# TC37XPD register map
Vendor: Infineon; Series: ATVMC; File version: 100
CPU: other r0p0, little endian, MPU, FPU, vendor SysTick, 4 interrupt priority bits
Registers are 32-bit, read-write, reset 0x0 unless marked. A register's access mark holds for its fields unless they carry their own. Offsets are from the block's base; [hi:lo] are bit positions; {n}, {i} and the like mark numbered series.

## MSC0 — MSC
Base 0xF0002600
Same registers: MSC1 0xF0002700
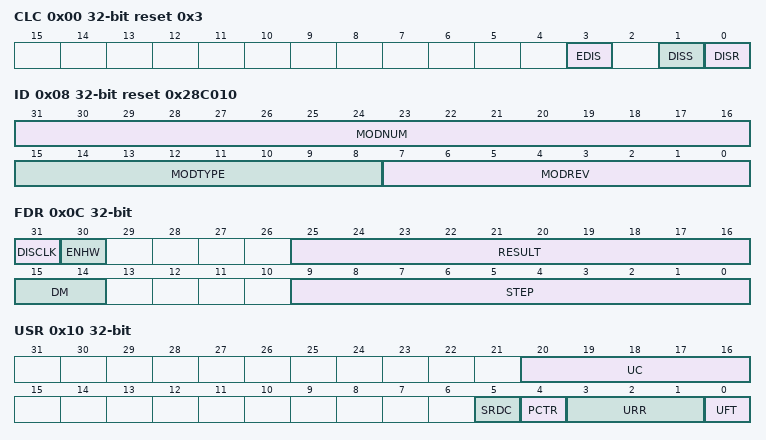
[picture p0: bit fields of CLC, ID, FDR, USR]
0x00 CLC access per field reset 0x3 — Clock Control Register resetvalue={Application Reset:0x3}
  [3] EDIS rw — Sleep Mode Enable Control EDIS. Used to control module 8217 s sleep mode.
  [1] DISS ro — Module Disable Status Bit DISS. Bit indicates the current status of the module.
  [0] DISR rw — Module Disable Request Bit DISR. Used for enable disable control of the module.
0x08 ID ro reset 0x28C010 (reset mask 0xFFFFFFF0) — Module Identification Register resetvalue={Application Reset:0x28C010}
  [31:16] MODNUM — Module Number Value MODNUM. This bit field defines the module identification number for the MSC 0028 H
  [15:8] MODTYPE — Module Type MODTYPE. This bit field defines the module as a 32 bit module C0 H
  [7:0] MODREV — Module Revision Number MODREV. This bit field defines the module revision number. The value of a module revision starts with 01 H first revision .
0x0C FDR access per field — Fractional Divider Register resetvalue={Application Reset:0x0}
  [31] DISCLK rw — Disable Clock DISCLK. Hardware controlled disable for f MSC signal.
  [30] ENHW rw — Enable Hardware Clock Control ENHW. Controls operation of ECEN input and DISCLK bit.
  [25:16] RESULT ro — Result Value RESULT. Bit field for the addition result.
  [15:14] DM rw — Divider Mode DM. DM selects normal or fractional divider mode.
  [9:0] STEP rw — Step Value STEP. Reload or addition value for RESULT.
0x10 USR access per field — Upstream Status Register resetvalue={Application Reset:0x0}
  [20:16] UC ro — Upstream Counter UC. This bit field indicates the content of the upstream counter that counts the bits during upstream channel reception.
  [5] SRDC rw — Service Request Delay Control SRDC. This bit determines the additional delay inserted by the upstream channel when triggering the receive interrupt. Only the hardware generated interrupt can be delayed. The software generated interrupt by writing the ISC.SURDI bit is never delayed.
  [4] PCTR rw — Parity Control PCTR. This bit determines the parity mode used by the upstream channel for data reception.
  [3:1] URR rw — Upstream Channel Receiving Rate URR. This bit field determines the baud rate for the upstream channel.
  [0] UFT rw — Upstream Channel Frame Type UFT. This bit determines the frame type used by the upstream channel for data reception.
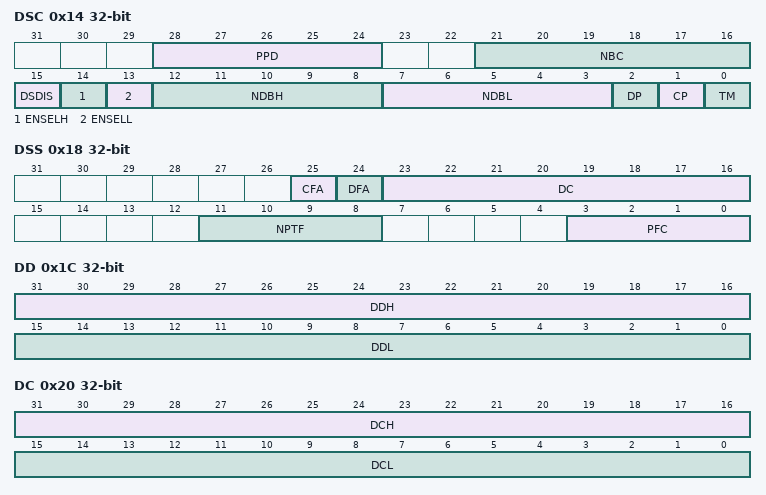
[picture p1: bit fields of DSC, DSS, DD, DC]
0x14 DSC access per field — Downstream Control Register resetvalue={Application Reset:0x0}
  [28:24] PPD rw — Passive Phase Length at Data Frames PPD. This bit field determines the length of the passive phase of a data frame.
  [21:16] NBC rw — Number of Bits Shifted at Command Frames NBC. This bit field determines how many bits of the SRL SRH shift registers are shifted out during transmission of a command frame.
  [15] DSDIS ro — Downstream Disable DSDIS. This bit indicates the state of the downstream channel operation.
  [14] ENSELH rw — Enable SRH Active Phase Selection Bit ENSELH. This bit determines whether a low level selection bit is inserted at the beginning of a data frame 8217 s SRH active phase.
  [13] ENSELL rw — Enable SRL Active Phase Selection Bit ENSELL. This bit determines whether a low level selection bit is inserted at the beginning of a data frame 8217 s SRL active phase.
  [12:8] NDBH rw — Number of SRH Bits Shifted at Data Frames NDBH. NDBH determines the number of shift register high part SRH bits that are shifted out on SO during a data frame. Other bit combinations are reserved do not use these bit combinations.
  [7:3] NDBL rw — Number of SRL Bits Shifted at Data Frames NDBL. NDBL determines the number of shift register low part SRL bits that are shifted out on SO during a data frame. Other bit combinations are reserved do not use these bit combinations.
  [2] DP ro — Data Pending DP. In Triggered Mode this bit is set when the set data pending bit ISC.SDP is set by software. In Data Repetition Mode this bit is set by hardware at the last passive time frame. At the start of the data frame DP is cleared by hardware.
  [1] CP ro — Command Pending CP. This bit is set when the downstream command register DC is written. CP is cleared when the first bit of the related command frame is sent out.
  [0] TM rw — Transmission Mode TM. This bit selects the transmission mode of the downstream channel.
0x18 DSS access per field — Downstream Status Register resetvalue={Application Reset:0x0}
  [25] CFA ro — Command Frame Active CFA. This bit indicates if a command frame is currently sent out active phase only.
  [24] DFA ro — Data Frame Active DFA. This bit indicates if a data frame is currently sent out active phase only.
  [23:16] DC ro — Downstream Counter DC. This bit field indicates the number of downstream shift clock periods that have been elapsed since the start of the current frame. DC is reset at the end of a downstream frame.
  [11:8] NPTF rw — Number Of Passive Time Frames NPTF. This bit field indicates the number of passive time frames that are inserted in Data Repetition Mode between two data frames.
  [3:0] PFC ro — Passive Time Frame Counter PFC. In Data Repetition Mode this bit field indicates the count of passive time frames that are currently transmitted. In Triggered Mode PFC remains at 0000 B .
0x1C DD — Downstream Data Register resetvalue={Application Reset:0x0}
  [31:16] DDH — Downstream Data for SRH Shift Register DDH. Contains the data bits to be transmitted during the SRH active phase of a data frame.
  [15:0] DDL — Downstream Data for SRL Shift Register DDL. Contains the data bits to be transmitted during the SRL active phase of a data frame.
0x20 DC — Downstream Command Register resetvalue={Application Reset:0x0}
  [31:16] DCH — Downstream Command for SRH Shift Register DCH. Contains the data bits to be transmitted during the SRH active phase of a command frame.
  [15:0] DCL — Downstream Command for SRL Shift Register DCL. Contains the data bits to be transmitted during the SRL active phase of a command frame.
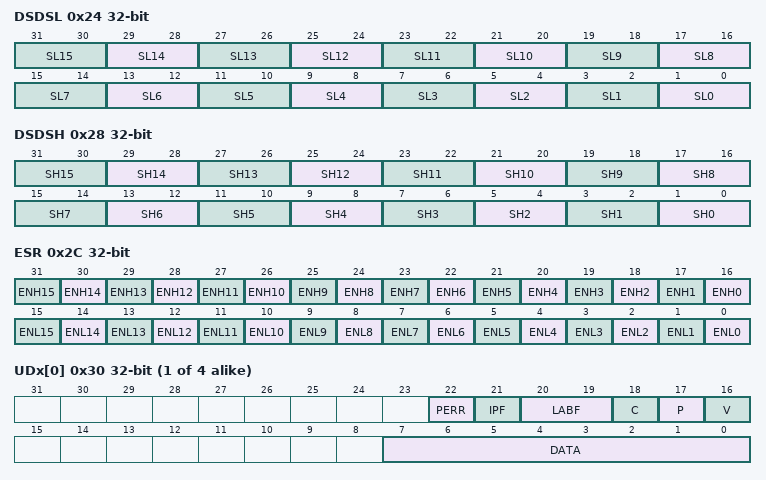
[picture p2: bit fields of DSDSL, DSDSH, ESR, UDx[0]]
0x24 DSDSL — Downstream Select Data Source Low Register resetvalue={Application Reset:0x0}
  [2n+1:2n] SL{n} (n=0..15) — Select Source for SRL SL15. SLx determines which data source is used for the shift register bit SRL x for data frame transmission.
0x28 DSDSH — Downstream Select Data Source High Register resetvalue={Application Reset:0x0}
  [2n+1:2n] SH{n} (n=0..15) — Select Source for SRH SH15. SHx determines which data source is used for the shift register bit SRH x during data frame transmission.
0x2C ESR — Emergency Stop Register resetvalue={Application Reset:0x0}
  [n+16] ENH{n} (n=0..15) — Emergency Stop Enable for Bit 15 in SRH ENH15. This bit enables the emergency stop feature selectively for each SRH bit. If the emergency stop condition is met and enabled ENHx 1 the SRH x bit of the data register DD.DDH x is used for the shift register load operation.
  [n] ENL{n} (n=0..15) — Emergency Stop Enable for Bit 15 in SRL ENL15. This bit enables the emergency stop feature selectively for each SRL bit. If the emergency stop condition is met and enabled ENLx 1 the SRL x bit of the data register DD.DDL x is used for the shift register load operation.
{0x30+4i} UDx[{i}] (i=0..3) access per field — Upstream Data Register 0 resetvalue={Application Reset:0x0}
  [22] PERR ro — Parity Error PERR. This bit indicates if a start bit error parity error or stop bit error occurred during frame reception.
  [21] IPF ro — Internal Parity Flag IPF. This bit contains the parity bit that has been calculated in the MSC during data frame reception.
  [20:19] LABF ro — Lower Address Bit Field LABF. This bit field contains the two address bits A 1 0 of the 4 bit address field 16 bit data frame . If 12 bit data frame is selected LABF is always set to 00 B .
  [18] C wo — Clear Bit C. C is always read as 0.
  [17] P ro — Parity Bit P. This flag contains the parity bit that has been received with the data frame.
  [16] V ro — Valid Bit V. This bit is set by hardware when the received data is written to UDx. Writing bit C 1 clears V. If hardware setting and software clearing of the valid bit occur simultaneously bit V will be cleared.
  [7:0] DATA ro — Received Data DATA. This bit field contains the 8 bit receive data.
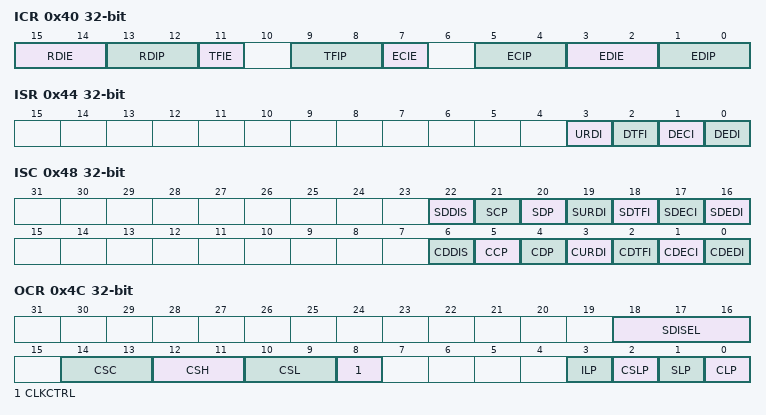
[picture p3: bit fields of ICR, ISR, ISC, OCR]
0x40 ICR — Interrupt Control Register resetvalue={Application Reset:0x0}
  [15:14] RDIE — Receive Data Interrupt Enable RDIE. This bit field determines the enable conditions for the receive data interrupt.
  [13:12] RDIP — Receive Data Interrupt Pointer RDIP. RDIP selects the service request output line SRn n 0 3 for the receive data interrupt.
  [11] TFIE — Time Frame Interrupt Enable TFIE. This bit enables the time frame interrupt.
  [9:8] TFIP — Time Frame Interrupt Pointer TFIP. TFIP selects the service request output line SRn n 0 3 for the time frame interrupt.
  [7] ECIE — Command Frame Interrupt Enable ECIE. This bit enables the command frame interrupt.
  [5:4] ECIP — Command Frame Interrupt Node Pointer ECIP. ECIP selects the service request output line SRn n 0 3 for the command frame interrupt.
  [3:2] EDIE — Data Frame Interrupt Enable EDIE. This bit field determines the enable conditions for the data frame interrupt.
  [1:0] EDIP — Data Frame Interrupt Node Pointer EDIP. EDIP selects the service request output line SRn n 0 3 for the data frame interrupt.
0x44 ISR ro — Interrupt Status Register resetvalue={Application Reset:0x0}
  [3] URDI — Receive Data Interrupt Flag URDI. This flag is always set by hardware when an upstream channel receive data interrupt is generated whether or not it is enabled. URDI can be set or cleared by software when writing to register ISC with the appropriate bits SURDI or CURDI set.
  [2] DTFI — Time Frame Interrupt Flag DTFI. This flag is always set by hardware when a downstream channel time frame interrupt is generated whether or not it is enabled. DTFI can be set or cleared by software when writing to register ISC with the appropriate bits SDTFI or CDTFI set.
  [1] DECI — Command Frame Interrupt Flag DECI. This flag is always set by hardware when a downstream channel command frame interrupt is generated whether or not it is enabled. DECI can be set or cleared by software when writing to register ISC with the appropriate bits SDECI or CDECI set.
  [0] DEDI — Data Frame Interrupt Flag DEDI. This flag is always set by hardware when a downstream channel data frame interrupt is generated. DEDI can be set or cleared by software when writing to register ISC with the appropriate bits ISC.SDEDI or ISC.CDEDI set.
0x48 ISC wo — Interrupt Set Clear Register resetvalue={Application Reset:0x0}
  [22] SDDIS — Set DSDIS Flag SDDIS
  [21] SCP — Set CP Flag SCP
  [20] SDP — Set DP Bit SDP
  [19] SURDI — Set URDI Flag SURDI
  [18] SDTFI — Set DTFI Flag SDTFI
  [17] SDECI — Set DECI Flag SDECI
  [16] SDEDI — Set DEDI Flag SDEDI
  [6] CDDIS — Clear DSDIS Flag CDDIS
  [5] CCP — Clear CP Flag CCP
  [4] CDP — Clear DP Flag CDP
  [3] CURDI — Clear URDI Flag CURDI
  [2] CDTFI — Clear DTFI Flag CDTFI
  [1] CDECI — Clear DECI Flag CDECI
  [0] CDEDI — Clear DEDI Flag CDEDI
0x4C OCR — Output Control Register resetvalue={Application Reset:0x0}
  [18:16] SDISEL — Serial Data Input Selection SDISEL. This bit field selects the source for the serial data input SDI of the upstream channel.
  [14:13] CSC — Chip Enable Selection for ENC CSC. This bit field selects the chip enable output ENx that becomes active during the active phase ENC 160 160 1 of a command frame. The active level of ENx is defined by bit CSLP.
  [12:11] CSH — Chip Enable Selection for ENH CSH. This bit field selects the chip enable output ENx that becomes active during the SRH active phase ENH 160 160 1 of a data frame. The active level of ENx is defined by bit CSLP.
  [10:9] CSL — Chip Enable Selection for ENL CSL. This bit field selects the chip enable output ENx that becomes active during the SRL active phase ENL 160 160 1 of a data frame. The active level of ENx is defined by bit CSLP.
  [8] CLKCTRL — Clock Control CLKCTRL. This bit determines the activation of clock output FCL.
  [3] ILP — SDI Line Polarity ILP
  [2] CSLP — Chip Selection Lines Polarity CSLP. Bit CSLP is buffered during a frame transmission. This means that any change of CSLP becomes valid first with the start of the next frame transmission.
  [1] SLP — SOP Line Polarity SLP
  [0] CLP — FCLP Line Polarity CLP
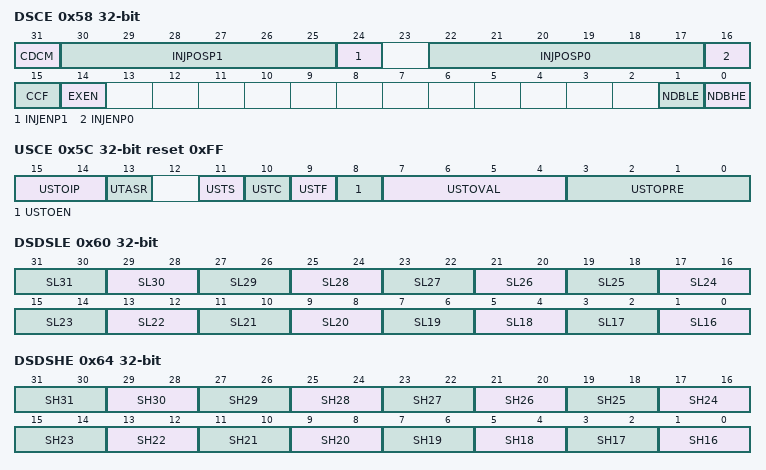
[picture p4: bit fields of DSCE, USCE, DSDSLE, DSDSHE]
0x58 DSCE access per field — Downstream Control Enhanced Register 1 resetvalue={Application Reset:0x0}
  [31] CDCM rw — Command Data Command in Data Repetition Mode CDCM. This bit selects if a data frame is automatically inserted between two consecutive command frame requests.
  [30:25] INJPOSP1 rw — Injection Position of the Pin 1 Signal INJPOSP1. This bit selects the position of the injected external one bit signal at the bit position in range of 0 to 63 in the data frame.
  [24] INJENP1 rw — Injection Enable of the Pin 1 Signal INJENP1. This bit selects if an external signal is injected in a data frame.
  [22:17] INJPOSP0 rw — Injection Position of the Pin 0 Signal INJPOSP0. This bit selects the position of the injected external one bit signal at the bit position in range of 0 to 63 in the data frame. If both PIN0POS and PIN1POS point to a same bit PIN0POS has the higher priority that is PIN0 level will be visible in the data frame.
  [16] INJENP0 rw — Injection Enable of the Pin 0 Signal INJENP0. This bit selects if an external signal is injected in a data frame.
  [15] CCF ro — Command Command Flag CCF. This bit flags that a second command frame has been written without data frame to be sent in between. It is active only if CDCM 1. Otherwise it is always low.
  [14] EXEN rw — Extension Enable EXEN. Enables the extension bit fields.
  [1] NDBLE rw — Number of SRL Bits Shifted at Data Frames Extension NDBLE. Additional MSB bit extension of the NDBL bit field. Adds 16 to the resulting NDBL value if set.
  [0] NDBHE rw — Number of SRH Bits Shifted at Data Frames Extension NDBHE. Additional MSB bit extension of the NDBH bit field. Adds 16 to the resulting NDBH value if set.
0x5C USCE access per field reset 0xFF — Upstream Control Enhanced Register 1 resetvalue={Application Reset:0x0FF}
  [15:14] USTOIP rw — Upstream Time out Interrupt Node Pointer USTOIP. USTOIP selects the service request output line SRn n 0 3 for the time out interrupt.
  [13] UTASR rw — Upstream Time out Alternate Service Request UTASR. Selects if the interrupt signal is routed to the alternate service request node. See CROSSREFERENCE .
  [11] USTS wo — Upstream Time out Set USTS. Sets the USTF flag. Write only bit reads as 0.
  [10] USTC wo — Upstream Time out Clear USTC. Clears the USTF flag. Write only bit reads as 0.
  [9] USTF ro — Upstream Time out Flag USTF. Signals an upstream timer event. If set by software the interrupt is also triggered if enabled. The watchdog timer runs continuously and sets the USTF flag at overflow independently from the enable bit. Therefore this bit must be cleared with the same write access which enables the interrupt.
  [8] USTOEN rw — Upstream Time out Interrupt Enable USTOEN. Enable bit for the upstream time out interrupt. The Time out counter runs continuously independently of the USTOEN bit. The USTOEN enables only the interrupt generation.
  [7:4] USTOVAL rw — Upstream Time out Value USTOVAL. Upstream time out value for the N divider in the range of 1 to 16 expressed in number of upstream bit time lengths the upstream bit time is the reciprocal value of the upstream baud rate . Time out BitTime 2 USTOPRE 1 USTOVAL 1 . Write to this bit field triggers new start of the watchdog timer.
  [3:0] USTOPRE rw — Upstream Time out Prescaler USTOPRE. Prescaler for the upstream time out limit. Expressed in upstream bit times. 2 n divider in the range of 1 to 16384. Write to this bit field triggers new start of the watchdog timer.
0x60 DSDSLE — Downstream Select Data Source Low Extension Register resetvalue={Application Reset:0x0}
  [2n-31:2n-32] SL{n} (n=16..31) — Select Source for SRL SL31. SLx determines which data source is used for the shift register bit SRL x during data frame transmission.
0x64 DSDSHE — Downstream Select Data Source High Extension Register resetvalue={Application Reset:0x0}
  [2n-31:2n-32] SH{n} (n=16..31) — Select Source for SRH SH31. SHx determines which data source is used for the shift register bit SRH x during data frame transmission.
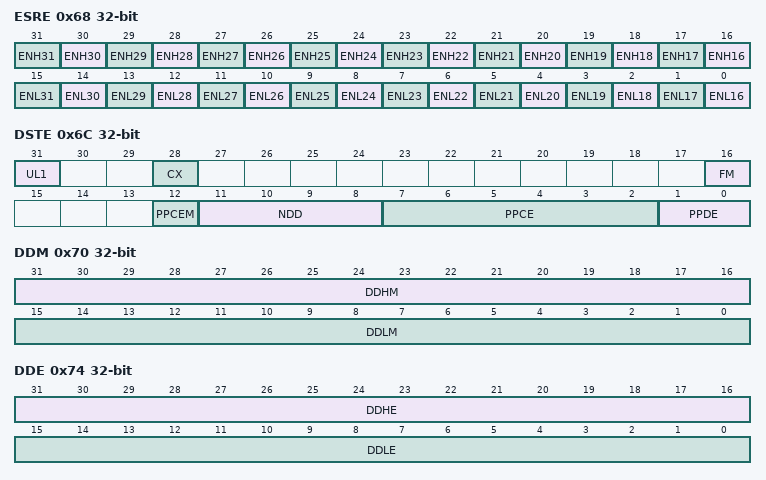
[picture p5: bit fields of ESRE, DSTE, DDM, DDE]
0x68 ESRE — Emergency Stop Extension Register resetvalue={Application Reset:0x0}
  [n] ENH{n} (n=16..31) — Emergency Stop Enable for Bit 31 in SRH ENH31. This bit enables the emergency stop feature selectively for each SRH bit. If the emergency stop condition is met and enabled ENHx 1 the SRH x bit of the data register DD.DDH x is used for the shift register load operation.
  [n-16] ENL{n} (n=16..31) — Emergency Stop Enable for Bit 31 in SRL ENL31. This bit enables the emergency stop feature selectively for each SRL bit. If the emergency stop condition is met and enabled ENLx 1 the SRL x bit is of the data register DD.DDL x is used for the shift register load operation.
0x6C DSTE access per field — Downstream Timing Extension Register resetvalue={Application Reset:0x0}
  [31] UL1 wo — Unlock CX and FM for one write access UL1. Write access with UL1 160 160 1 unlocks the CX and FM bit fields for the current write access. Write accesses to these bit fields with UL1 160 160 0 do not have any effect. Returns zero on read.
  [28] CX rw — Command Extension Mode CX. Activates 64 bit command frame feature.
  [16] FM rw — Fast Mode FM. Activates the fast mode and writing to the ABRA FIFO with 100 160 MBaud input baud rate in order to provide 80MBaud output baud rate. It is also recommended for baud rate of 26 67 160 MBaud as defined in the CROSSREFERENCE . FM 0 is the compatibility setting with the previous generations of the MSC.
  [12] PPCEM rw — PPCE Extension Bit on the MSB Side PPCEM. This bit is the MSB extension bit for the PPCE bit field extending command frame passive phase to the value of 127. The values of 128 and 129 are not allowed.
  [11:8] NDD rw — N Divider Downstream NDD. Defines the division ratio in the range of 1 to 16.
  [7:2] PPCE rw — Passive Phase Length at Control Frames Extension PPCE. Additional MSB bits extension of the fixed length of 2 of the command frames passive phase. The final length is 2 160 160 PPCE resulting in a range of 2 to 65.
  [1:0] PPDE rw — Passive Phase Length at Data Frames Extension PPDE. Additional MSB bits extension of the PPD bit field.
0x70 DDM wo — Downstream Data Mirror Register resetvalue={Application Reset:0x0}
  [31:16] DDHM — Downstream Data Mirror for SRH Shift Register DDHM. Contains the data bits to be transmitted during the SRH active phase of a data frame.
  [15:0] DDLM — Downstream Data Mirror for SRL Shift Register DDLM. Contains the data bits to be transmitted during the SRL active phase of a data frame.
0x74 DDE — Downstream Data Extension Register resetvalue={Application Reset:0x0}
  [31:16] DDHE — Downstream Data Extension for SRH Shift Register DDHE. Contains the data bits to be transmitted during the SRH active phase of a data frame.
  [15:0] DDLE — Downstream Data Extension for SRL Shift Register DDLE. Contains the data bits to be transmitted during the SRL active phase of a data frame.
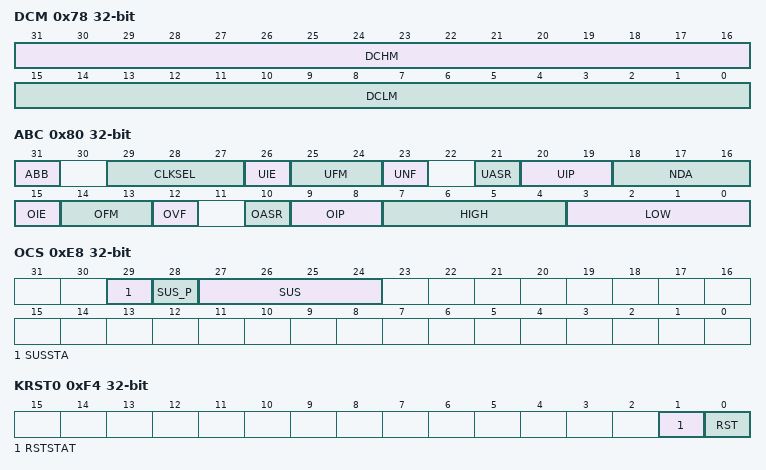
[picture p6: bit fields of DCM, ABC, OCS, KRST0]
0x78 DCM wo — Downstream Command Mirror Register resetvalue={Application Reset:0x0}
  [31:16] DCHM — Downstream Command Mirror of the DC.DCH Bit Field DCHM. Contains the alternate write location for the command bits to be transmitted during the SRH active phase of a command frame.
  [15:0] DCLM — Downstream Command Mirror of the DC.DCL Bit Field DCLM. Contains alternate write location for the command bits to be transmitted during the SRL active phase of a command frame.
0x7C DCE — Downstream Command Extension Register resetvalue={Application Reset:0x0}
  [31:0] DCEH — Downstream Command Extension for SRH Shift Register DCEH. Contains the data bits to be transmitted during the second half of the command frame in CX mode.
0x80 ABC access per field — Asynchronous Block Configuration Register resetvalue={Application Reset:0x0}
  [31] ABB rw — Asynchronous Block Bypass ABB. Defines if the asynchronous block and the n divider of the MSC downstream path located parallel to the fractional divider are used or not. If bypassed then also disabled.
  [29:27] CLKSEL rw — Clock Select CLKSEL. Selects the clock source for the ABRA block.
  [26] UIE rw — Underflow Interrupt Enable UIE. Enables or disables the path of the interrupt signal towards the interrupt node. If enabled an underflow event triggers an interrupt and if disabled then not. The UNF flag always indicates the occurrence of an underflow event independently of UIE.
  [25:24] UFM wo — Underflow Flag Modify UFM. Sets or clears the underflow flag UNF.
  [23] UNF ro — Underflow Flag UNF. Indicates if underflow error has occurred.
  [21] UASR rw — Underflow Alternate Service Request UASR. Selects if the interrupt signal is routed to the alternate service request node. See CROSSREFERENCE .
  [20:19] UIP rw — Underflow Interrupt Node Pointer UIP. UIP selects the service request output line SRn n 160 160 0 3 for the underflow interrupt.
  [18:16] NDA rw — N Divider ABRA NDA. Defines the division ratio in the range of 1 to 8.
  [15] OIE rw — Overflow Interrupt Enable OIE. Enables or disables the path of the interrupt signal towards the interrupt node. If enabled an overflow event triggers an interrupt and if disabled then not. The OVF flag always indicates the occurrence of an overflow event independently of OIE.
  [14:13] OFM wo — Overflow Flag Modify OFM. Sets or clears the overflow flag OVF.
  [12] OVF ro — Overflow Flag OVF. Indicates if overflow error has occurred.
  [10] OASR rw — Overflow Alternate Service Request OASR. Selects if the interrupt signal is routed to the alternate service request node. See CROSSREFERENCE .
  [9:8] OIP rw — Overflow Interrupt Node Pointer OIP. OIP selects the service request output line SRn n 0 3 for the overflow interrupt.
  [7:4] HIGH rw — Duration of the High Phase of the Shift Clock HIGH. Defines the duration of the high phase of the shift clock in periods of f A in the range of 1 to 16.
  [3:0] LOW rw — Duration of the Low Phase of the Shift Clock LOW. Defines the duration of the low phase of the shift clock in periods of f A in the range of 1 to 16.
0xE8 OCS access per field — OCDS Control and Status resetvalue={Debug Reset:0x0}
  [29] SUSSTA ro — Suspend State SUSSTA
  [28] SUS_P wo — SUS Write Protection SUS P. SUS is only written when SUS P is 1 otherwise unchanged. Read as 0.
  [27:24] SUS rw — OCDS Suspend Control SUS. Controls the sensitivity to the suspend signal coming from the OCDS Trigger Switch OTGS
0xEC KRSTCLR wo — Kernel Reset Status Clear Register resetvalue={Application Reset:0x0}
  [0] CLR — Kernel Reset Status Clear CLR. Read always as 0.
0xF0 KRST1 — Kernel Reset Register 1 resetvalue={Application Reset:0x0}
  [0] RST — Kernel Reset RST. This reset bit can be used to request for a kernel reset. The kernel reset will be executed if the reset bits of both kernel reset registers is set. The RST bit will be cleared reset to 0 by the BPI FPI after the kernel reset was executed.
0xF4 KRST0 access per field — Kernel Reset Register 0 resetvalue={Application Reset:0x0}
  [1] RSTSTAT ro — Kernel Reset Status RSTSTAT. This bit indicates wether a kernel reset was executed or not. This bit is set by the BPI FPI after the execution of a kernel reset in the same clock cycle both reset bits. This bit can be cleared by writing with 180 1 180 to the CLR bit in the related KRSTCLR register.
  [0] RST rw — Kernel Reset RST. This reset bit can be used to request for a kernel reset. The kernel reset will be executed if the reset bits of both kernel registers are set. The RST bit will be cleared reset to 180 0 180 by the BPI FPI after the kernel reset was executed.
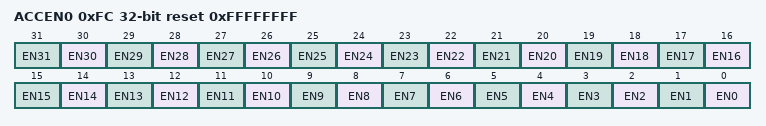
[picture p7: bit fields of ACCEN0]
0xFC ACCEN0 reset 0xFFFFFFFF — Access Enable Register 0 resetvalue={Application Reset:0x0FFFFFFFF}
  [n] EN{n} (n=0..31) — Access Enable for Master TAG ID 31 EN31. This bit enables write access to the module kernel addresses for transactions with the Master TAG ID n
